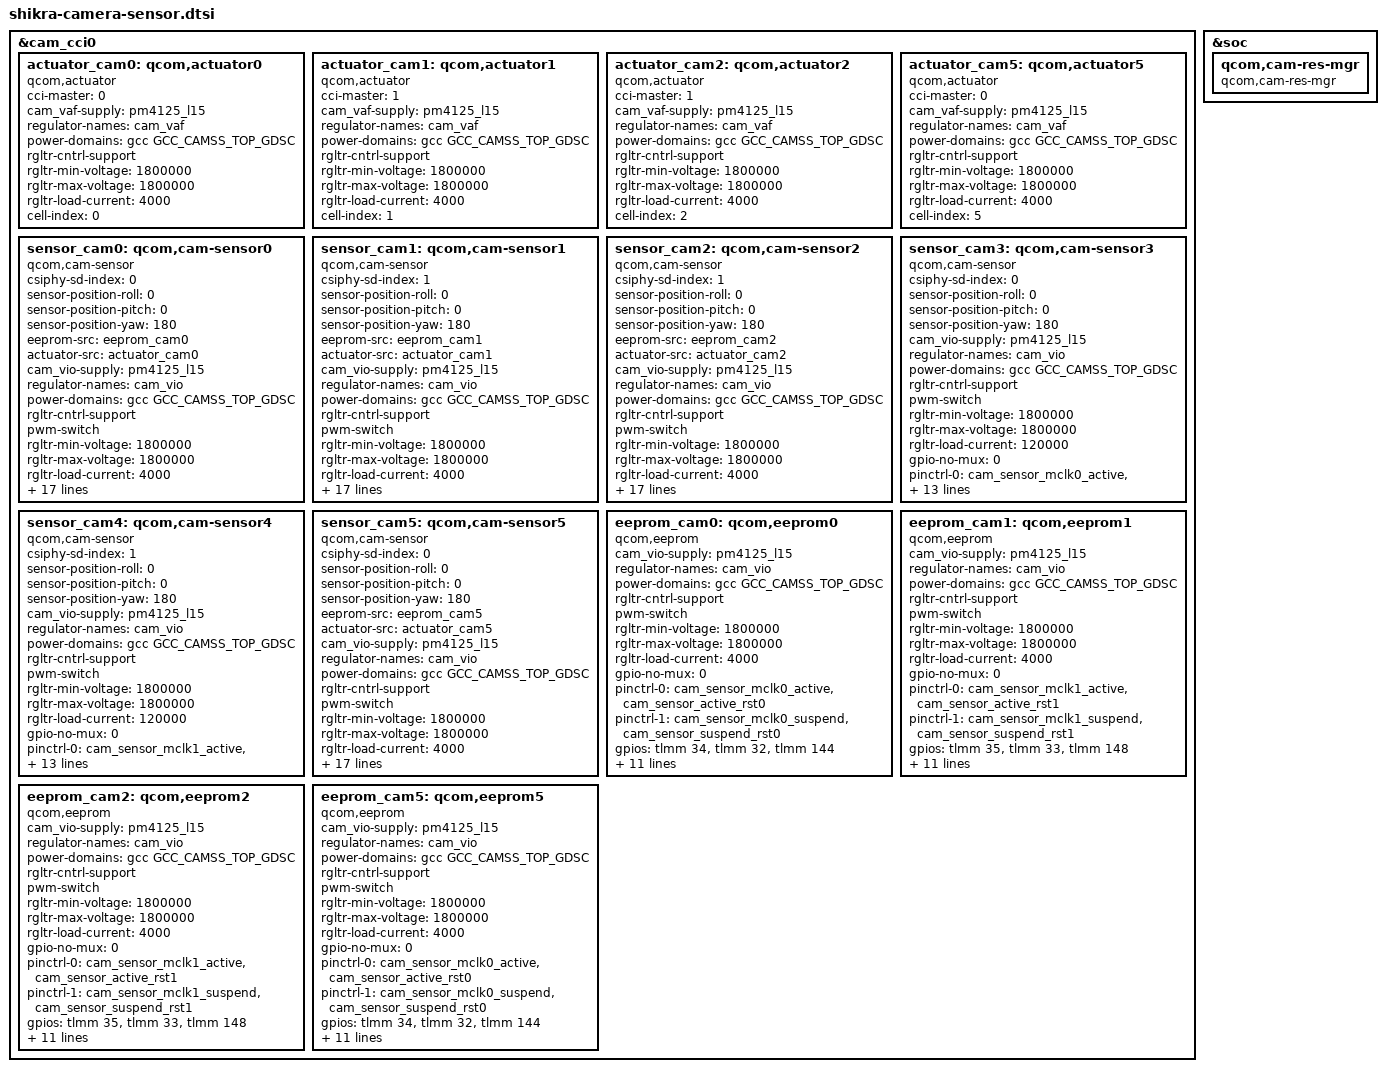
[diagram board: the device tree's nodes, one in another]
// SPDX-License-Identifier: BSD-3-Clause
/*
 * Copyright (c) Qualcomm Technologies, Inc. and/or its subsidiaries.
 */
#include <dt-bindings/camera/msm-camera.h>
#include <dt-bindings/gpio/gpio.h>

&cam_cci0 {
	actuator_cam0: qcom,actuator0 {
		compatible = "qcom,actuator";
		cci-master = <0>;
		cam_vaf-supply = <&pm4125_l15>;
		regulator-names = "cam_vaf";
		power-domains = <&gcc GCC_CAMSS_TOP_GDSC>;
		rgltr-cntrl-support;
		rgltr-min-voltage = <1800000>;
		rgltr-max-voltage = <1800000>;
		rgltr-load-current = <4000>;
		cell-index = <0>;
		status = "okay";
	};

	actuator_cam1: qcom,actuator1 {
		compatible = "qcom,actuator";
		cci-master = <1>;
		cam_vaf-supply = <&pm4125_l15>;
		regulator-names = "cam_vaf";
		power-domains = <&gcc GCC_CAMSS_TOP_GDSC>;
		rgltr-cntrl-support;
		rgltr-min-voltage = <1800000>;
		rgltr-max-voltage = <1800000>;
		rgltr-load-current = <4000>;
		cell-index = <1>;
		status = "okay";
	};

	actuator_cam2: qcom,actuator2 {
		compatible = "qcom,actuator";
		cci-master = <1>;
		cam_vaf-supply = <&pm4125_l15>;
		regulator-names = "cam_vaf";
		power-domains = <&gcc GCC_CAMSS_TOP_GDSC>;
		rgltr-cntrl-support;
		rgltr-min-voltage = <1800000>;
		rgltr-max-voltage = <1800000>;
		rgltr-load-current = <4000>;
		cell-index = <2>;
		status = "okay";
	};

	actuator_cam5: qcom,actuator5 {
		compatible = "qcom,actuator";
		cci-master = <0>;
		cam_vaf-supply = <&pm4125_l15>;
		regulator-names = "cam_vaf";
		power-domains = <&gcc GCC_CAMSS_TOP_GDSC>;
		rgltr-cntrl-support;
		rgltr-min-voltage = <1800000>;
		rgltr-max-voltage = <1800000>;
		rgltr-load-current = <4000>;
		cell-index = <5>;
		status = "okay";
	};

	/*cam0: OV13B10*/
	sensor_cam0: qcom,cam-sensor0 {
		compatible = "qcom,cam-sensor";
		csiphy-sd-index = <0>;
		sensor-position-roll = <0>;
		sensor-position-pitch = <0>;
		sensor-position-yaw = <180>;
		eeprom-src = <&eeprom_cam0>;
		actuator-src = <&actuator_cam0>;
		cam_vio-supply = <&pm4125_l15>;
		regulator-names = "cam_vio";
		power-domains = <&gcc GCC_CAMSS_TOP_GDSC>;
		rgltr-cntrl-support;
		pwm-switch;
		rgltr-min-voltage = <1800000>;
		rgltr-max-voltage = <1800000>;
		rgltr-load-current = <4000>;
		gpio-no-mux = <0>;
		pinctrl-names = "cam_default", "cam_suspend";
		pinctrl-0 = <&cam_sensor_mclk0_active
			     &cam_sensor_active_rst0>;
		pinctrl-1 = <&cam_sensor_mclk0_suspend
			     &cam_sensor_suspend_rst0>;
		gpios = <&tlmm 34 0>,
			<&tlmm 32 0>,
			<&tlmm 144 0>;
		gpio-reset = <1>;
		gpio-custom1 = <2>;
		gpio-req-tbl-num = <0 1 2>;
		gpio-req-tbl-flags = <1 0 0>;
		gpio-req-tbl-label = "CAM_MCLK0",
				     "CAMIF_RESET0",
				     "CAM_CUSTOM1";
		cci-master = <0>;
		clocks = <&gcc GCC_CAMSS_MCLK0_CLK>;
		clock-names = "cam_clk";
		clock-cntl-level = "nominal";
		clock-rates = <24000000>;
		cell-index = <0>;
		status = "okay";
	};

	/*cam1: OV13B10 */
	sensor_cam1: qcom,cam-sensor1 {
		compatible = "qcom,cam-sensor";
		csiphy-sd-index = <1>;
		sensor-position-roll = <0>;
		sensor-position-pitch = <0>;
		sensor-position-yaw = <180>;
		eeprom-src = <&eeprom_cam1>;
		actuator-src = <&actuator_cam1>;
		cam_vio-supply = <&pm4125_l15>;
		regulator-names = "cam_vio";
		power-domains = <&gcc GCC_CAMSS_TOP_GDSC>;
		rgltr-cntrl-support;
		pwm-switch;
		rgltr-min-voltage = <1800000>;
		rgltr-max-voltage = <1800000>;
		rgltr-load-current = <4000>;
		gpio-no-mux = <0>;
		pinctrl-names = "cam_default", "cam_suspend";
		pinctrl-0 = <&cam_sensor_mclk1_active
			     &cam_sensor_active_rst1>;
		pinctrl-1 = <&cam_sensor_mclk1_suspend
			     &cam_sensor_suspend_rst1>;
		gpios = <&tlmm 35 0>,
			<&tlmm 33 0>,
			<&tlmm 148 0>;
		gpio-reset = <1>;
		gpio-custom1 = <2>;
		gpio-req-tbl-num = <0 1 2>;
		gpio-req-tbl-flags = <1 0 0>;
		gpio-req-tbl-label = "CAM_MCLK1",
				     "CAMIF_RESET1",
				     "CAM_CUSTOM1";
		cci-master = <1>;
		clocks = <&gcc GCC_CAMSS_MCLK1_CLK>;
		clock-names = "cam_clk";
		clock-cntl-level = "nominal";
		clock-rates = <24000000>;
		cell-index = <1>;
		status = "okay";
	};

	/*cam2: IMX858 */
	sensor_cam2: qcom,cam-sensor2 {
		compatible = "qcom,cam-sensor";
		csiphy-sd-index = <1>;
		sensor-position-roll = <0>;
		sensor-position-pitch = <0>;
		sensor-position-yaw = <180>;
		eeprom-src = <&eeprom_cam2>;
		actuator-src = <&actuator_cam2>;
		cam_vio-supply = <&pm4125_l15>;
		regulator-names = "cam_vio";
		power-domains = <&gcc GCC_CAMSS_TOP_GDSC>;
		rgltr-cntrl-support;
		pwm-switch;
		rgltr-min-voltage = <1800000>;
		rgltr-max-voltage = <1800000>;
		rgltr-load-current = <4000>;
		gpio-no-mux = <0>;
		pinctrl-names = "cam_default", "cam_suspend";
		pinctrl-0 = <&cam_sensor_mclk1_active
			     &cam_sensor_active_rst1>;
		pinctrl-1 = <&cam_sensor_mclk1_suspend
			     &cam_sensor_suspend_rst1>;
		gpios = <&tlmm 35 0>,
			<&tlmm 33 0>,
			<&tlmm 148 0>;
		gpio-reset = <1>;
		gpio-custom1 = <2>;
		gpio-req-tbl-num = <0 1 2>;
		gpio-req-tbl-flags = <1 0 0>;
		gpio-req-tbl-label = "CAM_MCLK1",
				     "CAMIF_RESET1",
				     "CAM_CUSTOM1";
		cci-master = <1>;
		clocks = <&gcc GCC_CAMSS_MCLK1_CLK>;
		clock-names = "cam_clk";
		clock-cntl-level = "nominal";
		clock-rates = <19200000>;
		cell-index = <2>;
		status = "okay";
	};

	/*cam0: IMX577 - 22pin connector*/
	sensor_cam3: qcom,cam-sensor3 {
		compatible = "qcom,cam-sensor";
		csiphy-sd-index = <0>;
		sensor-position-roll = <0>;
		sensor-position-pitch = <0>;
		sensor-position-yaw = <180>;
		cam_vio-supply = <&pm4125_l15>;
		regulator-names = "cam_vio";
		power-domains = <&gcc GCC_CAMSS_TOP_GDSC>;
		rgltr-cntrl-support;
		pwm-switch;
		rgltr-min-voltage = <1800000>;
		rgltr-max-voltage = <1800000>;
		rgltr-load-current = <120000>;
		gpio-no-mux = <0>;
		pinctrl-names = "cam_default", "cam_suspend";
		pinctrl-0 = <&cam_sensor_mclk0_active
			     &cam_sensor_active_rst0>;
		pinctrl-1 = <&cam_sensor_mclk0_suspend
			     &cam_sensor_suspend_rst0>;
		gpios = <&tlmm 34 0>,
			<&tlmm 32 0>;
		gpio-reset = <1>;
		gpio-req-tbl-num = <0 1>;
		gpio-req-tbl-flags = <1 0>;
		gpio-req-tbl-label = "CAM_MCLK0",
				     "CAMIF_RESET0";
		cci-master = <0>;
		clocks = <&gcc GCC_CAMSS_MCLK0_CLK>;
		clock-names = "cam_clk";
		clock-cntl-level = "nominal";
		clock-rates = <24000000>;
		cell-index = <3>;
		status = "okay";
	};

	/*cam1: IMX577 - 22pin connector*/
	sensor_cam4: qcom,cam-sensor4 {
		compatible = "qcom,cam-sensor";
		csiphy-sd-index = <1>;
		sensor-position-roll = <0>;
		sensor-position-pitch = <0>;
		sensor-position-yaw = <180>;
		cam_vio-supply = <&pm4125_l15>;
		regulator-names = "cam_vio";
		power-domains = <&gcc GCC_CAMSS_TOP_GDSC>;
		rgltr-cntrl-support;
		pwm-switch;
		rgltr-min-voltage = <1800000>;
		rgltr-max-voltage = <1800000>;
		rgltr-load-current = <120000>;
		gpio-no-mux = <0>;
		pinctrl-names = "cam_default", "cam_suspend";
		pinctrl-0 = <&cam_sensor_mclk1_active
			     &cam_sensor_active_rst1>;
		pinctrl-1 = <&cam_sensor_mclk1_suspend
			     &cam_sensor_suspend_rst1>;
		gpios = <&tlmm 35 0>,
			<&tlmm 33 0>;
		gpio-reset = <1>;
		gpio-req-tbl-num = <0 1>;
		gpio-req-tbl-flags = <1 0>;
		gpio-req-tbl-label = "CAM_MCLK1",
				     "CAMIF_RESET1";
		cci-master = <1>;
		clocks = <&gcc GCC_CAMSS_MCLK1_CLK>;
		clock-names = "cam_clk";
		clock-cntl-level = "nominal";
		clock-rates = <24000000>;
		cell-index = <4>;
		status = "okay";
	};

	/*cam5: IMX858*/
	sensor_cam5: qcom,cam-sensor5 {
		compatible = "qcom,cam-sensor";
		csiphy-sd-index = <0>;
		sensor-position-roll = <0>;
		sensor-position-pitch = <0>;
		sensor-position-yaw = <180>;
		eeprom-src = <&eeprom_cam5>;
		actuator-src = <&actuator_cam5>;
		cam_vio-supply = <&pm4125_l15>;
		regulator-names = "cam_vio";
		power-domains = <&gcc GCC_CAMSS_TOP_GDSC>;
		rgltr-cntrl-support;
		pwm-switch;
		rgltr-min-voltage = <1800000>;
		rgltr-max-voltage = <1800000>;
		rgltr-load-current = <4000>;
		gpio-no-mux = <0>;
		pinctrl-names = "cam_default", "cam_suspend";
		pinctrl-0 = <&cam_sensor_mclk0_active
			     &cam_sensor_active_rst0>;
		pinctrl-1 = <&cam_sensor_mclk0_suspend
			     &cam_sensor_suspend_rst0>;
		gpios = <&tlmm 34 0>,
			<&tlmm 32 0>,
			<&tlmm 144 0>;
		gpio-reset = <1>;
		gpio-custom1 = <2>;
		gpio-req-tbl-num = <0 1 2>;
		gpio-req-tbl-flags = <1 0 0>;
		gpio-req-tbl-label = "CAM_MCLK0",
				     "CAMIF_RESET0",
				     "CAM_CUSTOM1";
		cci-master = <0>;
		clocks = <&gcc GCC_CAMSS_MCLK0_CLK>;
		clock-names = "cam_clk";
		clock-cntl-level = "nominal";
		clock-rates = <19200000>;
		cell-index = <5>;
		status = "okay";
	};

	/*EEPROM0: OV13B10 */
	eeprom_cam0: qcom,eeprom0 {
		compatible = "qcom,eeprom";
		cam_vio-supply = <&pm4125_l15>;
		regulator-names = "cam_vio";
		power-domains = <&gcc GCC_CAMSS_TOP_GDSC>;
		rgltr-cntrl-support;
		pwm-switch;
		rgltr-min-voltage = <1800000>;
		rgltr-max-voltage = <1800000>;
		rgltr-load-current = <4000>;
		gpio-no-mux = <0>;
		pinctrl-names = "cam_default", "cam_suspend";
		pinctrl-0 = <&cam_sensor_mclk0_active
			     &cam_sensor_active_rst0>;
		pinctrl-1 = <&cam_sensor_mclk0_suspend
			     &cam_sensor_suspend_rst0>;
		gpios = <&tlmm 34 0>,
			<&tlmm 32 0>,
			<&tlmm 144 0>;
		gpio-reset = <1>;
		gpio-custom1 = <2>;
		gpio-req-tbl-num = <0 1 2>;
		gpio-req-tbl-flags = <1 0 0>;
		gpio-req-tbl-label = "CAM_MCLK0",
				     "CAMIF_RESET0",
				     "CAM_CUSTOM1";
		cci-master = <0>;
		clocks = <&gcc GCC_CAMSS_MCLK0_CLK>;
		clock-names = "cam_clk";
		clock-cntl-level = "nominal";
		clock-rates = <24000000>;
		cell-index = <0>;
		status = "okay";
	};

	/*EEPROM1: OV13B10 */
	eeprom_cam1: qcom,eeprom1 {
		compatible = "qcom,eeprom";
		cam_vio-supply = <&pm4125_l15>;
		regulator-names = "cam_vio";
		power-domains = <&gcc GCC_CAMSS_TOP_GDSC>;
		rgltr-cntrl-support;
		pwm-switch;
		rgltr-min-voltage = <1800000>;
		rgltr-max-voltage = <1800000>;
		rgltr-load-current = <4000>;
		gpio-no-mux = <0>;
		pinctrl-names = "cam_default", "cam_suspend";
		pinctrl-0 = <&cam_sensor_mclk1_active
			     &cam_sensor_active_rst1>;
		pinctrl-1 = <&cam_sensor_mclk1_suspend
			     &cam_sensor_suspend_rst1>;
		gpios = <&tlmm 35 0>,
			<&tlmm 33 0>,
			<&tlmm 148 0>;
		gpio-reset = <1>;
		gpio-custom1 = <2>;
		gpio-req-tbl-num = <0 1 2>;
		gpio-req-tbl-flags = <1 0 0>;
		gpio-req-tbl-label = "CAM_MCLK1",
				     "CAMIF_RESET1",
				     "CAM_CUSTOM1";
		cci-master = <1>;
		clocks = <&gcc GCC_CAMSS_MCLK1_CLK>;
		clock-names = "cam_clk";
		clock-cntl-level = "nominal";
		clock-rates = <24000000>;
		cell-index = <1>;
		status = "okay";
	};

	/*EEPROM2: IMX858 */
	eeprom_cam2: qcom,eeprom2 {
		compatible = "qcom,eeprom";
		cam_vio-supply = <&pm4125_l15>;
		regulator-names = "cam_vio";
		power-domains = <&gcc GCC_CAMSS_TOP_GDSC>;
		rgltr-cntrl-support;
		pwm-switch;
		rgltr-min-voltage = <1800000>;
		rgltr-max-voltage = <1800000>;
		rgltr-load-current = <4000>;
		gpio-no-mux = <0>;
		pinctrl-names = "cam_default", "cam_suspend";
		pinctrl-0 = <&cam_sensor_mclk1_active
			     &cam_sensor_active_rst1>;
		pinctrl-1 = <&cam_sensor_mclk1_suspend
			     &cam_sensor_suspend_rst1>;
		gpios = <&tlmm 35 0>,
			<&tlmm 33 0>,
			<&tlmm 148 0>;
		gpio-reset = <1>;
		gpio-custom1 = <2>;
		gpio-req-tbl-num = <0 1 2>;
		gpio-req-tbl-flags = <1 0 0>;
		gpio-req-tbl-label = "CAM_MCLK1",
				     "CAMIF_RESET1",
				     "CAM_CUSTOM1";
		cci-master = <1>;
		clocks = <&gcc GCC_CAMSS_MCLK1_CLK>;
		clock-names = "cam_clk";
		clock-cntl-level = "nominal";
		clock-rates = <19200000>;
		cell-index = <2>;
		status = "okay";
	};

	/*EEPROM5: IMX858 */
	eeprom_cam5: qcom,eeprom5 {
		compatible = "qcom,eeprom";
		cam_vio-supply = <&pm4125_l15>;
		regulator-names = "cam_vio";
		power-domains = <&gcc GCC_CAMSS_TOP_GDSC>;
		rgltr-cntrl-support;
		pwm-switch;
		rgltr-min-voltage = <1800000>;
		rgltr-max-voltage = <1800000>;
		rgltr-load-current = <4000>;
		gpio-no-mux = <0>;
		pinctrl-names = "cam_default", "cam_suspend";
		pinctrl-0 = <&cam_sensor_mclk0_active
			     &cam_sensor_active_rst0>;
		pinctrl-1 = <&cam_sensor_mclk0_suspend
			     &cam_sensor_suspend_rst0>;
		gpios = <&tlmm 34 0>,
			<&tlmm 32 0>,
			<&tlmm 144 0>;
		gpio-reset = <1>;
		gpio-custom1 = <2>;
		gpio-req-tbl-num = <0 1 2>;
		gpio-req-tbl-flags = <1 0 0>;
		gpio-req-tbl-label = "CAM_MCLK0",
				     "CAMIF_RESET0",
				     "CAM_CUSTOM1";
		cci-master = <0>;
		clocks = <&gcc GCC_CAMSS_MCLK0_CLK>;
		clock-names = "cam_clk";
		clock-cntl-level = "nominal";
		clock-rates = <19200000>;
		cell-index = <5>;
		status = "okay";
	};
};

&soc {
	qcom,cam-res-mgr {
		compatible = "qcom,cam-res-mgr";
		status = "okay";
	};
};
